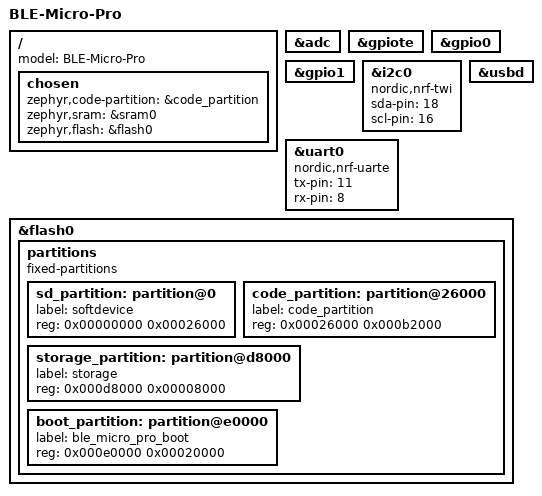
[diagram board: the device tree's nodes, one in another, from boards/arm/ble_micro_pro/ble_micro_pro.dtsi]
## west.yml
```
manifest:
  remotes:
    - name: zephyrproject-rtos
      url-base: https://github.com/zephyrproject-rtos
    - name: zmkfirmware
      url-base: https://github.com/zmkfirmware
  projects:
    - name: zephyr
      url: https://github.com/sekigon-gonnoc/zephyr
      revision: v4.1.0+nemu-link
      clone-depth: 1
      import:
        name-blocklist:
          - acpica
          - canopennode
          - cmsis-nn
          - cmsis_6
          - chre
          - ci-tools
          - edtt
          - fatfs
          - hal_adi
          - hal_altera
          - hal_ambiq
          - hal_atmel
          - hal_cypress
          - hal_espressif
          - hal_ethos_u
          - hal_gigadevice
          - hal_infineon
          - hal_intel
          - hal_microchip
          - hal_nuvoton
          - hal_nxp
          - hal_openisa
          - hal_quicklogic
          - hal_renesas
          - hal_rpi_pico
          - hal_silabs
          - hal_st
          - hal_stm32
          - hal_tdk
          - hal_telink
          - hal_ti
          - hal_wch
          - hal_wurthelektronik
          - hal_xtensa
          - hostap
          - liblc3
          - libmctp
          - libmetal
          - littlefs
          - loramac-node
          - lz4
          - mcuboot
          - mcumgr
          - mipi-sys-t
          - net-tools
          - nrf_hw_models
          - nrf_wifi
          - open-amp
          - openthread
          - percepio
          - psa-arch-tests
          - sof
          - tf-m-tests
          - tflite-micro
          - thrift
          - trusted-firmware-a
          - trusted-firmware-m
          - uoscore-uedhoc
          - zephyr-lang-rust
          - zscilib
    - name: lvgl
      revision: f1db87ee98f1810328a8419572fa42a3b5f352ae
      path: modules/lib/gui/lvgl
      remote: zmkfirmware
    - name: zmk-studio-messages
      url: https://github.com/sekigon-gonnoc/zmk-studio-messages
      revision: nemu-link
      path: modules/msgs/zmk-studio-messages
  group-filter: [+optional]
  self:
    west-commands: scripts/west-commands.yml
```

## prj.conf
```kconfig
CONFIG_APPLICATION_DEFINED_SYSCALL=y

# Use Zephyr's built-in Mbed TLS PSA backend for ZMK BLE crypto.
CONFIG_NRF_SECURITY=n
CONFIG_MBEDTLS_ENABLE_HEAP=y
CONFIG_MBEDTLS_HEAP_SIZE=4096
CONFIG_SETTINGS=y
CONFIG_ESB_MAX_PAYLOAD_LENGTH=64
CONFIG_SYSTEM_WORKQUEUE_STACK_SIZE=3072
CONFIG_ZMK_STUDIO_RPC_RX_BUF_SIZE=256
```

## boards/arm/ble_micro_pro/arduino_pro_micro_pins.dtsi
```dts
/*
 * Copyright (c) 2021 The ZMK Contributors
 *
 * SPDX-License-Identifier: MIT
 */

/ {
	pro_micro: connector {
		compatible = "arduino-pro-micro";
		#gpio-cells = <2>;
		gpio-map-mask = <0xffffffff 0xffffffc0>;
		gpio-map-pass-thru = <0 0x3f>;
		gpio-map
			= <0 0 &gpio0 8 0>		/* D0 */
			, <1 0 &gpio0 11 0>		/* D1 */
			, <2 0 &gpio0 18 0>		/* D2 */
			, <3 0 &gpio0 16 0>		/* D3 */
			, <4 0 &gpio0 19 0>		/* D4/A6 */
			, <5 0 &gpio0 20 0>		/* D5 */
			, <6 0 &gpio0 22 0>		/* D6/A7 */
			, <7 0 &gpio0 23 0>		/* D7 */
			, <8 0 &gpio1 0 0>		/* D8/A8 */
			, <9 0 &gpio1 3 0>		/* D9/A9 */
			, <10 0 &gpio0 9 0>		/* D10/A10 */
			, <16 0 &gpio0 10 0>	/* D16 */
			, <14 0 &gpio1 15 0>	/* D14 */
			, <15 0 &gpio1 14 0>	/* D15 */
			, <18 0 &gpio0 3 0>	/* D18/A0 */
			, <19 0 &gpio0 30 0>	/* D19/A1 */
			, <20 0 &gpio0 0 0>	/* D20/A2 */
			, <21 0 &gpio0 5 0>	/* D21/A3 */
			;
	};

	pro_micro_a: connector_a {
		compatible = "arduino-pro-micro";
		#gpio-cells = <2>;
		gpio-map-mask = <0xffffffff 0xffffffc0>;
		gpio-map-pass-thru = <0 0x3f>;
		gpio-map
			= <0 0 &gpio0 3 0>	/* D18/A0 */
			, <1 0 &gpio0 30 0>	/* D19/A1 */
			, <2 0 &gpio0 0 0>	/* D20/A2 */
			, <3 0 &gpio0 5 0>	/* D21/A3 */
			, <6 0 &gpio0 19 0>	/* D4/A6 */
			, <7 0 &gpio0 22 0>	/* D6/A7 */
			, <8 0 &gpio1 0 0>	/* D8/A8 */
			, <9 0 &gpio1 3 0>	/* D9/A9 */
			, <10 0 &gpio0 9 0>	/* D10/A10 */
			;
	};
};

pro_micro_d: &pro_micro {};
pro_micro_i2c: &i2c0 {};
pro_micro_spi: &spi0 {};
pro_micro_serial: &uart0 {};
```

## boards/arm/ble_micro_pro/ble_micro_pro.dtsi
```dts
/*
 * Copyright (c) 2021 The ZMK Contributors
 *
 * SPDX-License-Identifier: MIT
 */

#include <nordic/nrf52840_qiaa.dtsi>
#include "arduino_pro_micro_pins.dtsi"

/ {
	model = "BLE-Micro-Pro";

	chosen {
		zephyr,code-partition = &code_partition;
		zephyr,sram = &sram0;
		zephyr,flash = &flash0;
	};
};

&adc {
	status = "okay";
};

&gpiote {
	status = "okay";
};

&gpio0 {
	status = "okay";
};

&gpio1 {
	status = "okay";
};

&i2c0 {
	compatible = "nordic,nrf-twi";
	sda-pin = <18>;
	scl-pin = <16>;
};

&uart0 {
	compatible = "nordic,nrf-uarte";
	tx-pin = <11>;
	rx-pin = <8>;
};

&usbd {
	status = "okay";
};


&flash0 {
	/*
	 * For more information, see:
	 * http://docs.zephyrproject.org/latest/devices/dts/flash_partitions.html
	 */
	partitions {
		compatible = "fixed-partitions";
		#address-cells = <1>;
		#size-cells = <1>;

		sd_partition: partition@0 {
			label = "softdevice";
			reg = <0x00000000 0x00026000>;
		};
		code_partition: partition@26000 {
			label = "code_partition";
			reg = <0x00026000 0x000b2000>;
		};

		/*
		 * The flash starting at 0x000ec000 and ending at
		 * 0x000f3fff is reserved for use by the application.
		 */

		/*
		 * Storage partition will be used by FCB/LittleFS/NVS
		 * if enabled.
		 */
		storage_partition: partition@d8000 {
			label = "storage";
			reg = <0x000d8000 0x00008000>;
		};

		boot_partition: partition@e0000 {
			label = "ble_micro_pro_boot";
			reg = <0x000e0000 0x00020000>;
		};
	};
};
```

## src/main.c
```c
/*
 * Copyright (c) 2020 The ZMK Contributors
 *
 * SPDX-License-Identifier: MIT
 */

#include <zephyr/kernel.h>
#include <zephyr/device.h>
#include <zephyr/devicetree.h>
#include <zephyr/settings/settings.h>

#include <zephyr/logging/log.h>
LOG_MODULE_REGISTER(zmk, CONFIG_ZMK_LOG_LEVEL);

#if IS_ENABLED(CONFIG_ZMK_DISPLAY)

#include <zmk/display.h>
#include <lvgl.h>

#endif

int main(void) {
    LOG_INF("Welcome to ZMK!\n");

#if IS_ENABLED(CONFIG_SETTINGS)
    settings_subsys_init();
#if IS_ENABLED(CONFIG_ZMK_BEHAVIOR_LOCAL_ID_TYPE_SETTINGS_TABLE)
    settings_load_subtree("behavior");
#endif
    settings_load();
#endif

#ifdef CONFIG_ZMK_DISPLAY
    zmk_display_init();

#if IS_ENABLED(CONFIG_ARCH_POSIX)
    // Workaround for an SDL display issue:
    // https://github.com/zephyrproject-rtos/zephyr/issues/71410
    while (1) {
        lv_task_handler();
        k_sleep(K_MSEC(10));
    }
#endif

#endif /* CONFIG_ZMK_DISPLAY */

    return 0;
}
```

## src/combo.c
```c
/*
 * Copyright (c) 2020 The ZMK Contributors
 *
 * SPDX-License-Identifier: MIT
 */

#define DT_DRV_COMPAT zmk_combos

#include <zephyr/device.h>
#include <zephyr/logging/log.h>
#include <zephyr/sys/dlist.h>
#include <zephyr/sys/util.h>
#include <zephyr/kernel.h>

#include <drivers/behavior.h>

#include <zmk/behavior.h>
#include <zmk/event_manager.h>
#include <zmk/events/position_state_changed.h>
#include <zmk/events/keycode_state_changed.h>
#include <zmk/hid.h>
#include <zmk/matrix.h>
#include <zmk/keymap.h>
#include <zmk/virtual_key_position.h>

#if IS_ENABLED(CONFIG_ZMK_ESBR_RUNTIME_COMBO)
#include <zmk/esbr_runtime_combo/combo.h>
#endif
#if IS_ENABLED(CONFIG_ZMK_ESBR_RUNTIME_TAP_DANCE)
#include <zmk/esbr_runtime_tap_dance/tap_dance.h>
#endif

LOG_MODULE_DECLARE(zmk, CONFIG_ZMK_LOG_LEVEL);

#if DT_HAS_COMPAT_STATUS_OKAY(DT_DRV_COMPAT) || IS_ENABLED(CONFIG_ZMK_ESBR_RUNTIME_COMBO)

#if CONFIG_ZMK_COMBO_MAX_KEYS_PER_COMBO > 0

#warning                                                                                           \
    "CONFIG_ZMK_COMBO_MAX_KEYS_PER_COMBO is deprecated, and is auto-calculated from the devicetree now."

#endif

#if CONFIG_ZMK_COMBO_MAX_COMBOS_PER_KEY > 0

#warning "CONFIG_ZMK_COMBO_MAX_COMBOS_PER_KEY is deprecated, and is auto-calculated."

#endif

#if IS_ENABLED(CONFIG_ZMK_ESBR_RUNTIME_COMBO)
#define MAX_COMBO_KEYS ZMK_ESBR_RUNTIME_COMBO_MAX_POSITIONS
#define COMBO_COUNT ZMK_ESBR_RUNTIME_COMBO_MAX_SLOTS
#define BYTES_FOR_COMBOS_MASK 1
#else
#define COMBOS_KEYS_BYTE_ARRAY(node_id)                                                            \
    uint8_t _CONCAT(combo_prop_, node_id)[DT_PROP_LEN(node_id, key_positions)];

#define MAX_COMBO_KEYS sizeof(union {DT_INST_FOREACH_CHILD(0, COMBOS_KEYS_BYTE_ARRAY)})
#endif

struct combo_cfg {
    int32_t key_positions[MAX_COMBO_KEYS];
    int16_t key_position_len;
    int16_t require_prior_idle_ms;
    int32_t timeout_ms;
    uint32_t layer_mask;
    struct zmk_behavior_binding behavior;
    // if slow release is set, the combo releases when the last key is released.
    // otherwise, the combo releases when the first key is released.
    bool slow_release;
};

struct active_combo {
    uint16_t combo_idx;
    // key_positions_pressed is filled with key_positions when the combo is pressed.
    // The keys are removed from this array when they are released.
    // Once this array is empty, the behavior is released.
    uint16_t key_positions_pressed_count;
    struct zmk_position_state_changed_event key_positions_pressed[MAX_COMBO_KEYS];
};

#define PROP_BIT_AT_IDX(n, prop, idx) BIT(DT_PROP_BY_IDX(n, prop, idx))

#define NODE_PROP_BITMASK(n, prop)                                                                 \
    COND_CODE_1(DT_NODE_HAS_PROP(n, prop),                                                         \
                (DT_FOREACH_PROP_ELEM_SEP(n, prop, PROP_BIT_AT_IDX, (|))), (0))

#define GET_KEY_POSITION_MASK_PORTION(idx, n) ((NODE_PROP_BITMASK(n, key_positions) >> idx) & 0xFF)

#define COMBO_INST(n, positions)                                                                   \
    COND_CODE_1(IS_EQ(DT_PROP_LEN(n, key_positions), positions),                                   \
                (                                                                                  \
                    {                                                                              \
                        .timeout_ms = DT_PROP(n, timeout_ms),                                      \
                        .require_prior_idle_ms = DT_PROP(n, require_prior_idle_ms),                \
                        .key_positions = DT_PROP(n, key_positions),                                \
                        .key_position_len = DT_PROP_LEN(n, key_positions),                         \
                        .behavior = ZMK_KEYMAP_EXTRACT_BINDING(0, n),                              \
                        .slow_release = DT_PROP(n, slow_release),                                  \
                        .layer_mask = NODE_PROP_BITMASK(n, layers),                                \
                    }, ),                                                                          \
                ())

#define COMBO_CONFIGS_WITH_MATCHING_POSITIONS_LEN(positions, _ignore)                              \
    DT_INST_FOREACH_CHILD_VARGS(0, COMBO_INST, positions)

// We do some magic here to generate the `combos` array by "key position length", looping
// by key position length and on each iteration, only include entries where the `key-positions`
// length matches.
// Doing so allows our bitmasks to be "shorted key positions list first" when searching for matches.
// `20` is chosen as a reasonable limit, since the theoretical maximum number of keys you might
// reasonably press simultaneously with 10 fingers is 20 keys, two keys per finger.
#define COMBO_ONE(n) +1

#if DT_HAS_COMPAT_STATUS_OKAY(DT_DRV_COMPAT)
#define COMBO_CHILDREN_COUNT (0 DT_INST_FOREACH_CHILD(0, COMBO_ONE))
#else
#define COMBO_CHILDREN_COUNT 0
#endif

#if IS_ENABLED(CONFIG_ZMK_ESBR_RUNTIME_COMBO)
BUILD_ASSERT(COMBO_CHILDREN_COUNT == 0, "Runtime Combo cannot be combined with static ZMK combos");
static struct combo_cfg combos[COMBO_COUNT];
#define COMBO_TOTAL_COUNT COMBO_COUNT
#else
static const struct combo_cfg combos[] = {
    LISTIFY(20, COMBO_CONFIGS_WITH_MATCHING_POSITIONS_LEN, (), 0)};
#define COMBO_TOTAL_COUNT ARRAY_SIZE(combos)
#endif

// We need at least 4 bytes to avoid alignment issues
#if !IS_ENABLED(CONFIG_ZMK_ESBR_RUNTIME_COMBO)
#define BYTES_FOR_COMBOS_MASK MAX(1, DIV_ROUND_UP(COMBO_CHILDREN_COUNT, 32))
#endif

uint8_t pressed_keys_count = 0;
// set of keys pressed
struct zmk_position_state_changed_event pressed_keys[MAX_COMBO_KEYS] = {};
// the set of candidate combos based on the currently pressed_keys
uint32_t candidates[BYTES_FOR_COMBOS_MASK];
// the last candidate that was completely pressed
int16_t fully_pressed_combo = INT16_MAX;
// a lookup dict that maps a key position to all combos on that position
uint32_t combo_lookup[ZMK_KEYMAP_LEN][BYTES_FOR_COMBOS_MASK] = {};
// combos that have been activated and still have (some) keys pressed
// this array is always contiguous from 0.
struct active_combo active_combos[CONFIG_ZMK_COMBO_MAX_PRESSED_COMBOS] = {};
uint8_t active_combo_count = 0;

struct k_work_delayable timeout_task;
int64_t timeout_task_timeout_at;

// this keeps track of the last non-combo, non-mod key tap
int64_t last_tapped_timestamp = INT32_MIN;
// this keeps track of the last time a combo was pressed
int64_t last_combo_timestamp = INT32_MIN;

static void store_last_tapped(int64_t timestamp) {
    if (timestamp > last_combo_timestamp) {
        last_tapped_timestamp = timestamp;
    }
}

#if IS_ENABLED(CONFIG_ZMK_ESBR_RUNTIME_COMBO)
static void refresh_runtime_combos(void) {
    for (uint8_t i = 0; i < COMBO_COUNT; i++) {
        struct esbr_runtime_combo_config config;
        if (esbr_combo_slot_get(i, &config) != 0 || !config.enabled) {
            combos[i] = (struct combo_cfg){0};
            continue;
        }
        combos[i] = (struct combo_cfg){
            .key_position_len = config.count,
            .require_prior_idle_ms = 0,
            .timeout_ms = config.timeout_ms,
            .layer_mask = config.layer_mask,
            .behavior = config.binding,
            .slow_release = config.release_mode == 1,
        };
        for (uint8_t position = 0; position < config.count; position++) {
            combos[i].key_positions[position] = config.positions[position];
        }
    }
}

static bool runtime_combo_contains(const struct combo_cfg *combo, int32_t position) {
    for (int i = 0; i < combo->key_position_len; i++) {
        if (combo->key_positions[i] == position) {
            return true;
        }
    }
    return false;
}

static void runtime_combo_sync_busy(void) {
    bool busy[COMBO_COUNT] = {0};
    for (uint8_t i = 0; i < COMBO_COUNT; i++) {
        busy[i] = sys_bitfield_test_bit((mem_addr_t)&candidates, i);
    }
    for (uint8_t i = 0; i < active_combo_count; i++) {
        const uint16_t combo_idx = active_combos[i].combo_idx;
        if (combo_idx < COMBO_COUNT) {
            busy[combo_idx] = true;
        }
    }
    for (uint8_t i = 0; i < COMBO_COUNT; i++) {
        esbr_combo_slot_set_busy(i, busy[i]);
    }
}
#endif

// Store the combo key pointer in the combos array, one pointer for each key position
// The combos are sorted shortest-first, then by virtual-key-position.
static int initialize_combo(size_t index) {
    const struct combo_cfg *new_combo = &combos[index];

    for (size_t kp = 0; kp < new_combo->key_position_len; kp++) {
        sys_bitfield_set_bit((mem_addr_t)&combo_lookup[new_combo->key_positions[kp]], index);
    }

    return 0;
}

static bool combo_active_on_layer(const struct combo_cfg *combo, uint8_t layer) {
    if (!combo->layer_mask) {
        return true;
    }

    return combo->layer_mask & BIT(layer);
}

static bool is_quick_tap(const struct combo_cfg *combo, int64_t timestamp) {
    return (last_tapped_timestamp + combo->require_prior_idle_ms) > timestamp;
}

static int setup_candidates_for_first_keypress(int32_t position, int64_t timestamp) {
    int number_of_combo_candidates = 0;
    uint8_t highest_active_layer = zmk_keymap_highest_layer_active();

#if IS_ENABLED(CONFIG_ZMK_ESBR_RUNTIME_COMBO)
    for (size_t i = 0; i < COMBO_TOTAL_COUNT; i++) {
        const struct combo_cfg *combo = &combos[i];
        if (runtime_combo_contains(combo, position) &&
            combo_active_on_layer(combo, highest_active_layer) && !is_quick_tap(combo, timestamp)) {
            sys_bitfield_set_bit((mem_addr_t)&candidates, i);
            number_of_combo_candidates++;
        }
    }
#else
    for (size_t i = 0; i < COMBO_TOTAL_COUNT; i++) {
        if (sys_bitfield_test_bit((mem_addr_t)&combo_lookup[position], i)) {
            const struct combo_cfg *combo = &combos[i];
            if (combo_active_on_layer(combo, highest_active_layer) &&
                !is_quick_tap(combo, timestamp)) {
                sys_bitfield_set_bit((mem_addr_t)&candidates, i);
                number_of_combo_candidates++;
            }
            // LOG_DBG("combo timeout %d %d %d", position, i, candidates[i].timeout_at);
        }
    }
#endif

    return number_of_combo_candidates;
}

static inline uint8_t zero_one_or_more_bits(uint32_t field) {
    if (field == 0) {
        return 0;
    }
    if ((field & (field - 1)) == 0) {
        return 1;
    }
    return 2;
}

static int filter_candidates(int32_t position) {
    int matches = 0;
#if IS_ENABLED(CONFIG_ZMK_ESBR_RUNTIME_COMBO)
    for (size_t i = 0; i < COMBO_TOTAL_COUNT; i++) {
        if (!sys_bitfield_test_bit((mem_addr_t)&candidates, i)) {
            continue;
        }
        if (!runtime_combo_contains(&combos[i], position)) {
            sys_bitfield_clear_bit((mem_addr_t)&candidates, i);
        } else if (matches < 2) {
            matches++;
        }
    }
#else
    for (int i = 0; i < BYTES_FOR_COMBOS_MASK; i++) {
        candidates[i] &= combo_lookup[position][i];
        if (matches < 2) {
            matches += zero_one_or_more_bits(candidates[i]);
        }
    }
#endif

    LOG_DBG("combo matches after filter %d", matches);
    return matches;
}

static int64_t first_candidate_timeout() {
    if (pressed_keys_count == 0) {
        return LONG_MAX;
    }

    int64_t first_timeout = LONG_MAX;
    for (int i = 0; i < COMBO_TOTAL_COUNT; i++) {
        if (sys_bitfield_test_bit((mem_addr_t)&candidates, i)) {
            first_timeout = MIN(first_timeout, combos[i].timeout_ms);
        }
    }

    return pressed_keys[0].data.timestamp + first_timeout;
}

static inline bool candidate_is_completely_pressed(const struct combo_cfg *candidate) {
    // this code assumes set(pressed_keys) <= set(candidate->key_positions)
    // this invariant is enforced by filter_candidates
    // since events may have been reraised after clearing one or more slots at
    // the start of pressed_keys (see: release_pressed_keys), we have to check
    // that each key needed to trigger the combo was pressed, not just the last.
    return candidate->key_position_len == pressed_keys_count;
}

static int cleanup();

static int filter_timed_out_candidates(int64_t timestamp) {
    __ASSERT(pressed_keys_count > 0, "Searching for a candidate timeout with no keys pressed");

    int remaining_candidates = 0;
    for (int i = 0; i < COMBO_TOTAL_COUNT; i++) {
        if (sys_bitfield_test_bit((mem_addr_t)&candidates, i)) {

            if (pressed_keys[0].data.timestamp + combos[i].timeout_ms > timestamp) {
                remaining_candidates++;
            } else {
                sys_bitfield_clear_bit((mem_addr_t)&candidates, i);
            }
        }
    }

    LOG_DBG(
        "after filtering out timed out combo candidates: remaining_candidates=%d timestamp=%lld",
        remaining_candidates, timestamp);

    return remaining_candidates;
}

static int capture_pressed_key(const struct zmk_position_state_changed *ev) {
    if (pressed_keys_count == MAX_COMBO_KEYS) {
        return ZMK_EV_EVENT_BUBBLE;
    }

    pressed_keys[pressed_keys_count++] = copy_raised_zmk_position_state_changed(ev);
    return ZMK_EV_EVENT_CAPTURED;
}

const struct zmk_listener zmk_listener_combo;

static int release_pressed_keys() {
    uint8_t count = pressed_keys_count;
    pressed_keys_count = 0;
    for (int i = 0; i < count; i++) {
        struct zmk_position_state_changed_event *ev = &pressed_keys[i];
        if (i == 0) {
            LOG_DBG("combo: releasing position event %d", ev->data.position);
            ZMK_EVENT_RELEASE(*ev);
        } else {
            // reprocess events (see tests/combo/fully-overlapping-combos-3 for why this is needed)
            LOG_DBG("combo: reraising position event %d", ev->data.position);
            ZMK_EVENT_RAISE(*ev);
        }
    }

    return count;
}

static inline int press_combo_behavior(int combo_idx, const struct combo_cfg *combo,
                                       int32_t timestamp) {
    struct zmk_behavior_binding_event event = {
        .position = ZMK_VIRTUAL_KEY_POSITION_COMBO(combo_idx),
        .timestamp = timestamp,
#if IS_ENABLED(CONFIG_ZMK_SPLIT)
        .source = ZMK_POSITION_STATE_CHANGE_SOURCE_LOCAL,
#endif
    };

    last_combo_timestamp = timestamp;

    return zmk_behavior_invoke_binding(&combo->behavior, event, true);
}

static inline int release_combo_behavior(int combo_idx, const struct combo_cfg *combo,
                                         int32_t timestamp) {
    struct zmk_behavior_binding_event event = {
        .position = ZMK_VIRTUAL_KEY_POSITION_COMBO(combo_idx),
        .timestamp = timestamp,
#if IS_ENABLED(CONFIG_ZMK_SPLIT)
        .source = ZMK_POSITION_STATE_CHANGE_SOURCE_LOCAL,
#endif
    };

    return zmk_behavior_invoke_binding(&combo->behavior, event, false);
}

static void move_pressed_keys_to_active_combo(struct active_combo *active_combo) {

    int combo_length = MIN(pressed_keys_count, combos[active_combo->combo_idx].key_position_len);
    for (int i = 0; i < combo_length; i++) {
        active_combo->key_positions_pressed[i] = pressed_keys[i];
    }
    active_combo->key_positions_pressed_count = combo_length;

    // move any other pressed keys up
    for (int i = 0; i + combo_length < pressed_keys_count; i++) {
        pressed_keys[i] = pressed_keys[i + combo_length];
    }

    pressed_keys_count -= combo_length;
}

static struct active_combo *store_active_combo(int32_t combo_idx) {
    for (int i = 0; i < CONFIG_ZMK_COMBO_MAX_PRESSED_COMBOS; i++) {
        if (active_combos[i].combo_idx == UINT16_MAX) {
            active_combos[i].combo_idx = combo_idx;
            active_combo_count++;
            return &active_combos[i];
        }
    }
    LOG_ERR("Unable to store combo; already %d active. Increase "
            "CONFIG_ZMK_COMBO_MAX_PRESSED_COMBOS",
            CONFIG_ZMK_COMBO_MAX_PRESSED_COMBOS);
    return NULL;
}

static void activate_combo(int combo_idx) {
    struct active_combo *active_combo = store_active_combo(combo_idx);
    if (active_combo == NULL) {
        // unable to store combo
        release_pressed_keys();
        return;
    }
    move_pressed_keys_to_active_combo(active_combo);
    press_combo_behavior(combo_idx, &combos[combo_idx],
                         active_combo->key_positions_pressed[0].data.timestamp);
}

static void deactivate_combo(int active_combo_index) {
    active_combo_count--;
    if (active_combo_index != active_combo_count) {
        memcpy(&active_combos[active_combo_index], &active_combos[active_combo_count],
               sizeof(struct active_combo));
    }
    active_combos[active_combo_count] = (struct active_combo){0};
    active_combos[active_combo_count].combo_idx = UINT16_MAX;
}

/* returns true if a key was released. */
static bool release_combo_key(int32_t position, int64_t timestamp) {
    for (int combo_idx = 0; combo_idx < active_combo_count; combo_idx++) {
        struct active_combo *active_combo = &active_combos[combo_idx];

        bool key_released = false;
        bool all_keys_pressed = active_combo->key_positions_pressed_count ==
                                combos[active_combo->combo_idx].key_position_len;
        bool all_keys_released = true;
        for (int i = 0; i < active_combo->key_positions_pressed_count; i++) {
            if (key_released) {
                active_combo->key_positions_pressed[i - 1] = active_combo->key_positions_pressed[i];
                all_keys_released = false;
            } else if (active_combo->key_positions_pressed[i].data.position != position) {
                all_keys_released = false;
            } else { // position matches
                key_released = true;
            }
        }

        if (key_released) {
            active_combo->key_positions_pressed_count--;
            const struct combo_cfg *c = &combos[active_combo->combo_idx];
            if ((c->slow_release && all_keys_released) || (!c->slow_release && all_keys_pressed)) {
                release_combo_behavior(active_combo->combo_idx, c, timestamp);
            }
            if (all_keys_released) {
                deactivate_combo(combo_idx);
            }
            return true;
        }
    }
    return false;
}

static int cleanup() {
    k_work_cancel_delayable(&timeout_task);
    memset(candidates, 0, BYTES_FOR_COMBOS_MASK * sizeof(uint32_t));
    if (fully_pressed_combo != INT16_MAX) {
        activate_combo(fully_pressed_combo);
        fully_pressed_combo = INT16_MAX;
    }
    int released = release_pressed_keys();
#if IS_ENABLED(CONFIG_ZMK_ESBR_RUNTIME_COMBO)
    runtime_combo_sync_busy();
#endif
    return released;
}

static void update_timeout_task() {
    int64_t first_timeout = first_candidate_timeout();
    if (timeout_task_timeout_at == first_timeout) {
        return;
    }
    if (first_timeout == LLONG_MAX) {
        timeout_task_timeout_at = 0;
        k_work_cancel_delayable(&timeout_task);
        return;
    }
    if (k_work_schedule(&timeout_task, K_MSEC(first_timeout - k_uptime_get())) >= 0) {
        timeout_task_timeout_at = first_timeout;
    }
}

static int position_state_down(const zmk_event_t *ev, struct zmk_position_state_changed *data) {
    int num_candidates;
#if IS_ENABLED(CONFIG_ZMK_ESBR_RUNTIME_COMBO)
    refresh_runtime_combos();
#endif
    if (!pressed_keys_count) {
        num_candidates = setup_candidates_for_first_keypress(data->position, data->timestamp);
        if (num_candidates == 0) {
            return ZMK_EV_EVENT_BUBBLE;
        }
    } else {
        filter_timed_out_candidates(data->timestamp);
        num_candidates = filter_candidates(data->position);
    }

    LOG_DBG("combo: capturing position event %d", data->position);
    int ret = capture_pressed_key(data);
    update_timeout_task();
#if IS_ENABLED(CONFIG_ZMK_ESBR_RUNTIME_COMBO)
    runtime_combo_sync_busy();
#endif

    if (num_candidates) {
        for (int i = 0; i < COMBO_TOTAL_COUNT; i++) {
            if (sys_bitfield_test_bit((mem_addr_t)&candidates, i)) {
                const struct combo_cfg *candidate_combo = &combos[i];
                if (candidate_is_completely_pressed(candidate_combo)) {
                    fully_pressed_combo = i;
                    if (num_candidates == 1) {
                        cleanup();
                    }
                }

                return ret;
            }
        }
    } else {
        cleanup();
        return ret;
    }

    return -EINVAL;
}

static int position_state_up(const zmk_event_t *ev, struct zmk_position_state_changed *data) {
    int released_keys = cleanup();
    if (release_combo_key(data->position, data->timestamp)) {
#if IS_ENABLED(CONFIG_ZMK_ESBR_RUNTIME_COMBO)
        runtime_combo_sync_busy();
#endif
        return ZMK_EV_EVENT_HANDLED;
    }
    if (released_keys > 1) {
        // The second and further key down events are re-raised. To preserve
        // correct order for e.g. hold-taps, reraise the key up event too.
        struct zmk_position_state_changed_event dupe_ev =
            copy_raised_zmk_position_state_changed(data);
        ZMK_EVENT_RAISE(dupe_ev);
        return ZMK_EV_EVENT_CAPTURED;
    }
    return ZMK_EV_EVENT_BUBBLE;
}

static void combo_timeout_handler(struct k_work *item) {
    if (timeout_task_timeout_at == 0 || k_uptime_get() < timeout_task_timeout_at) {
        // timer was cancelled or rescheduled.
        return;
    }
    if (filter_timed_out_candidates(timeout_task_timeout_at) == 0) {
        LOG_DBG("CLEANUP!");
        cleanup();
    }
#if IS_ENABLED(CONFIG_ZMK_ESBR_RUNTIME_COMBO)
    runtime_combo_sync_busy();
#endif

    LOG_DBG("ABOUT TO UPDATE IN TIMEOUT");
    update_timeout_task();
}

static int position_state_changed_listener(const zmk_event_t *ev) {
    struct zmk_position_state_changed *data = as_zmk_position_state_changed(ev);
    if (data == NULL) {
        return ZMK_EV_EVENT_BUBBLE;
    }

#if IS_ENABLED(CONFIG_ZMK_ESBR_RUNTIME_TAP_DANCE)
    if (data->state) {
        esbr_tap_dance_position_interrupt(data->source, data->position, data->timestamp);
    }
#endif

    if (data->state) { // keydown
        return position_state_down(ev, data);
    } else { // keyup
        return position_state_up(ev, data);
    }
}

static int keycode_state_changed_listener(const zmk_event_t *eh) {
    struct zmk_keycode_state_changed *ev = as_zmk_keycode_state_changed(eh);
    if (ev->state && !is_mod(ev->usage_page, ev->keycode)) {
        store_last_tapped(ev->timestamp);
    }
    return ZMK_EV_EVENT_BUBBLE;
}

int behavior_combo_listener(const zmk_event_t *eh) {
    if (as_zmk_position_state_changed(eh) != NULL) {
        return position_state_changed_listener(eh);
    } else if (as_zmk_keycode_state_changed(eh) != NULL) {
        return keycode_state_changed_listener(eh);
    }
    return ZMK_EV_EVENT_BUBBLE;
}

ZMK_LISTENER(combo, behavior_combo_listener);
ZMK_SUBSCRIPTION(combo, zmk_position_state_changed);
ZMK_SUBSCRIPTION(combo, zmk_keycode_state_changed);

static int combo_init(void) {
    for (size_t i = 0; i < CONFIG_ZMK_COMBO_MAX_PRESSED_COMBOS; i++) {
        active_combos[i].combo_idx = UINT16_MAX;
    }

    k_work_init_delayable(&timeout_task, combo_timeout_handler);
    LOG_WRN("Have %d combos!", COMBO_TOTAL_COUNT);
#if IS_ENABLED(CONFIG_ZMK_ESBR_RUNTIME_COMBO)
    refresh_runtime_combos();
    runtime_combo_sync_busy();
#else
    for (int i = 0; i < COMBO_TOTAL_COUNT; i++) {
        initialize_combo(i);
    }
#endif
    return 0;
}

SYS_INIT(combo_init, APPLICATION, CONFIG_KERNEL_INIT_PRIORITY_DEFAULT);

#endif
```

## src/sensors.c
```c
/*
 * Copyright (c) 2020 The ZMK Contributors
 *
 * SPDX-License-Identifier: MIT
 */

#include <zephyr/drivers/sensor.h>
#include <zephyr/devicetree.h>
#include <zephyr/init.h>

#include <zephyr/logging/log.h>

LOG_MODULE_DECLARE(zmk, CONFIG_ZMK_LOG_LEVEL);

#include <zmk/sensors.h>
#include <zmk/event_manager.h>
#include <zmk/events/sensor_event.h>

#if ZMK_KEYMAP_HAS_SENSORS

struct sensors_item_cfg {
    const struct zmk_sensor_config *config;
    const struct device *dev;
    struct sensor_trigger trigger;
    uint8_t sensor_index;
};

#define _SENSOR_ITEM(idx, node)                                                                    \
    {                                                                                              \
        .dev = DEVICE_DT_GET_OR_NULL(node),                                                        \
        .trigger = {.type = SENSOR_TRIG_DATA_READY, .chan = SENSOR_CHAN_ROTATION},                 \
        .config = &configs[idx], .sensor_index = idx                                               \
    }
#define SENSOR_ITEM(idx, _i) _SENSOR_ITEM(idx, ZMK_KEYMAP_SENSORS_BY_IDX(idx))

#define PLUS_ONE(n) +1
#define ZMK_KEYMAP_SENSORS_CHILD_COUNT (0 DT_FOREACH_CHILD(ZMK_KEYMAP_SENSORS_NODE, PLUS_ONE))
#define SENSOR_CHILD_ITEM(node)                                                                    \
    {                                                                                              \
        .triggers_per_rotation =                                                                   \
            DT_PROP_OR(node, triggers_per_rotation,                                                \
                       DT_PROP_OR(ZMK_KEYMAP_SENSORS_NODE, triggers_per_rotation,                  \
                                  CONFIG_ZMK_KEYMAP_SENSORS_DEFAULT_TRIGGERS_PER_ROTATION))        \
    }
#define SENSOR_CHILD_DEFAULTS(idx, arg)                                                            \
    {                                                                                              \
        .triggers_per_rotation =                                                                   \
            DT_PROP_OR(ZMK_KEYMAP_SENSORS_NODE, triggers_per_rotation,                             \
                       CONFIG_ZMK_KEYMAP_SENSORS_DEFAULT_TRIGGERS_PER_ROTATION)                    \
    }

static struct zmk_sensor_config configs[] = {
#if ZMK_KEYMAP_SENSORS_CHILD_COUNT > 0
    DT_FOREACH_CHILD_SEP(ZMK_KEYMAP_SENSORS_NODE, SENSOR_CHILD_ITEM, (, ))
#else
    LISTIFY(ZMK_KEYMAP_SENSORS_LEN, SENSOR_CHILD_DEFAULTS, (, ), 0)
#endif
};

static struct sensors_item_cfg sensors[] = {LISTIFY(ZMK_KEYMAP_SENSORS_LEN, SENSOR_ITEM, (, ), 0)};

static ATOMIC_DEFINE(pending_sensors, ZMK_KEYMAP_SENSORS_LEN);

const struct zmk_sensor_config *zmk_sensors_get_config_at_index(uint8_t sensor_index) {
    if (sensor_index > ARRAY_SIZE(configs)) {
        return NULL;
    }

    return &configs[sensor_index];
}

static void trigger_sensor_data_for_position(uint32_t sensor_index) {
    int err;
    const struct sensors_item_cfg *item = &sensors[sensor_index];

    err = sensor_sample_fetch(item->dev);
    if (err) {
        LOG_WRN("Failed to fetch sample from device %d", err);
        return;
    }

    struct sensor_value value = {0};
    err = sensor_channel_get(item->dev, item->trigger.chan, &value);

    if (err) {
        LOG_WRN("Failed to get channel data from device %d", err);
        return;
    }

    raise_zmk_sensor_event(
        (struct zmk_sensor_event){.sensor_index = item->sensor_index,
                                  .channel_data_size = 1,
                                  .channel_data = {(struct zmk_sensor_channel_data){
                                      .value = value, .channel = item->trigger.chan}},
                                  .timestamp = k_uptime_get()});
}

static void run_sensors_data_trigger(struct k_work *work) {
    for (int i = 0; i < ARRAY_SIZE(sensors); i++) {
        if (atomic_test_and_clear_bit(pending_sensors, i)) {
            trigger_sensor_data_for_position(i);
        }
    }
}

K_WORK_DEFINE(sensor_data_work, run_sensors_data_trigger);

static void zmk_sensors_trigger_handler(const struct device *dev,
                                        const struct sensor_trigger *trigger) {
    const struct sensors_item_cfg *test_item =
        CONTAINER_OF(trigger, struct sensors_item_cfg, trigger);
    int sensor_index = test_item - sensors;

    if (sensor_index < 0 || sensor_index >= ARRAY_SIZE(sensors)) {
        LOG_ERR("Invalid sensor item triggered our callback (%d)", sensor_index);
        return;
    }

    if (k_is_in_isr()) {
        atomic_set_bit(pending_sensors, sensor_index);
        k_work_submit(&sensor_data_work);
    } else {
        trigger_sensor_data_for_position(sensor_index);
    }
}

static void zmk_sensors_init_item(uint8_t i) {
    LOG_DBG("Init sensor at index %d", i);

    if (!sensors[i].dev) {
        LOG_DBG("No local device for %d", i);
        return;
    }

    int err = sensor_trigger_set(sensors[i].dev, &sensors[i].trigger, zmk_sensors_trigger_handler);
    if (err) {
        LOG_WRN("Failed to set sensor trigger (%d)", err);
    }
}

#define SENSOR_INIT(idx, _t) zmk_sensors_init_item(idx);

static int zmk_sensors_init(void) {
    LISTIFY(ZMK_KEYMAP_SENSORS_LEN, SENSOR_INIT, (), 0)

    return 0;
}

SYS_INIT(zmk_sensors_init, APPLICATION, CONFIG_APPLICATION_INIT_PRIORITY);

#endif /* ZMK_KEYMAP_HAS_SENSORS */
```

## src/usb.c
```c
/*
 * Copyright (c) 2020 The ZMK Contributors
 *
 * SPDX-License-Identifier: MIT
 */

#include <zephyr/device.h>
#include <zephyr/init.h>

#include <zephyr/usb/usb_device.h>
#include <zephyr/usb/class/usb_hid.h>

#include <zmk/hid.h>
#include <zmk/keymap.h>
#include <zmk/event_manager.h>
#include <zmk/events/usb_conn_state_changed.h>

#include <zmk/usb_hid.h>

LOG_MODULE_DECLARE(zmk, CONFIG_ZMK_LOG_LEVEL);

static enum usb_dc_status_code usb_status = USB_DC_UNKNOWN;
static bool is_configured;

static void raise_usb_status_changed_event(struct k_work *_work) {
    raise_zmk_usb_conn_state_changed(
        (struct zmk_usb_conn_state_changed){.conn_state = zmk_usb_get_conn_state()});
}

K_WORK_DEFINE(usb_status_notifier_work, raise_usb_status_changed_event);

enum usb_dc_status_code zmk_usb_get_status(void) { return usb_status; }

enum zmk_usb_conn_state zmk_usb_get_conn_state(void) {
    // LOG_DBG("state: %d", usb_status);
    switch (usb_status) {
    case USB_DC_SUSPEND:
    case USB_DC_CONFIGURED:
    case USB_DC_RESUME:
    case USB_DC_CLEAR_HALT:
    case USB_DC_SOF:
        return ZMK_USB_CONN_HID;

    case USB_DC_DISCONNECTED:
    case USB_DC_UNKNOWN:
        return ZMK_USB_CONN_NONE;

    default:
        return ZMK_USB_CONN_POWERED;
    }
}

bool zmk_usb_is_hid_ready(void) {
    return zmk_usb_get_conn_state() == ZMK_USB_CONN_HID && is_configured;
}

void usb_status_cb(enum usb_dc_status_code status, const uint8_t *params) {
    // Start-of-frame and interface selection events do not change ZMK's USB
    // connection state. In particular, UAC alternate setting changes must not
    // make the configured HID/RPC endpoint appear disconnected.
    if (status == USB_DC_SOF || status == USB_DC_INTERFACE) {
        return;
    }

#if IS_ENABLED(CONFIG_ZMK_USB_BOOT)
    if (status == USB_DC_RESET) {
        zmk_usb_hid_set_protocol(HID_PROTOCOL_REPORT);
    }
#endif
    usb_status = status;
    if (zmk_usb_get_conn_state() == ZMK_USB_CONN_HID) {
        is_configured |= usb_status == USB_DC_CONFIGURED;
    } else {
        is_configured = false;
    }
    k_work_submit(&usb_status_notifier_work);
};

static int zmk_usb_init(void) {
    int usb_enable_ret;

    usb_enable_ret = usb_enable(usb_status_cb);

    if (usb_enable_ret != 0) {
        LOG_ERR("Unable to enable USB");
        return -EINVAL;
    }

    return 0;
}

SYS_INIT(zmk_usb_init, APPLICATION, CONFIG_ZMK_USB_INIT_PRIORITY);
```

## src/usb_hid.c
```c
/*
 * Copyright (c) 2020 The ZMK Contributors
 *
 * SPDX-License-Identifier: MIT
 */

#include <zephyr/device.h>
#include <zephyr/init.h>

#include <zephyr/usb/usb_device.h>
#include <zephyr/usb/class/usb_hid.h>

#ifdef CONFIG_ZMK_NEMU_LINK
#define NEMU_LINK_USB_FEATURE_REPORT
#endif
#include <zmk/usb.h>
#include <zmk/hid.h>
#if IS_ENABLED(CONFIG_ZMK_DEV_DEBUG_HID)
#include <zmk/dev_debug/hid.h>
#endif
#ifdef CONFIG_ZMK_NEMU_LINK
#include <zmk/nemu_link/hid_feature_report.h>
#endif
#include <zmk/keymap.h>

#if IS_ENABLED(CONFIG_ZMK_POINTING_SMOOTH_SCROLLING)
#include <zmk/pointing/resolution_multipliers.h>
#endif // IS_ENABLED(CONFIG_ZMK_POINTING_SMOOTH_SCROLLING)

#if IS_ENABLED(CONFIG_ZMK_HID_INDICATORS)
#include <zmk/hid_indicators.h>
#endif // IS_ENABLED(CONFIG_ZMK_HID_INDICATORS)

#include <zmk/event_manager.h>

LOG_MODULE_DECLARE(zmk, CONFIG_ZMK_LOG_LEVEL);

static const struct device *hid_dev;

static K_SEM_DEFINE(hid_sem, 1, 1);

static void in_ready_cb(const struct device *dev) { k_sem_give(&hid_sem); }

#define HID_GET_REPORT_TYPE_MASK 0xff00
#define HID_GET_REPORT_ID_MASK 0x00ff

#define HID_REPORT_TYPE_INPUT 0x100
#define HID_REPORT_TYPE_OUTPUT 0x200
#define HID_REPORT_TYPE_FEATURE 0x300

#if IS_ENABLED(CONFIG_ZMK_USB_BOOT)
static uint8_t hid_protocol = HID_PROTOCOL_REPORT;

static void set_proto_cb(const struct device *dev, uint8_t protocol) { hid_protocol = protocol; }

void zmk_usb_hid_set_protocol(uint8_t protocol) { hid_protocol = protocol; }
#endif /* IS_ENABLED(CONFIG_ZMK_USB_BOOT) */

static uint8_t *get_keyboard_report(size_t *len) {
#if IS_ENABLED(CONFIG_ZMK_USB_BOOT)
    if (hid_protocol != HID_PROTOCOL_REPORT) {
        zmk_hid_boot_report_t *boot_report = zmk_hid_get_boot_report();
        *len = sizeof(*boot_report);
        return (uint8_t *)boot_report;
    }
#endif
    struct zmk_hid_keyboard_report *report = zmk_hid_get_keyboard_report();
    *len = sizeof(*report);
    return (uint8_t *)report;
}

static int get_report_cb(const struct device *dev, struct usb_setup_packet *setup, int32_t *len,
                         uint8_t **data) {
    switch (setup->wValue & HID_GET_REPORT_TYPE_MASK) {
    case HID_REPORT_TYPE_FEATURE:
        switch (setup->wValue & HID_GET_REPORT_ID_MASK) {
#if IS_ENABLED(CONFIG_ZMK_DEV_DEBUG_HID)
        case ZMK_HID_REPORT_ID_DEV_DEBUG: {
            static uint8_t debug_report[ZMK_DEV_DEBUG_HID_REPORT_SIZE];
            int rc = zmk_dev_debug_hid_get_report(debug_report, sizeof(debug_report));
            if (rc) {
                return rc;
            }
            *len = sizeof(debug_report);
            *data = debug_report;
            break;
        }
#endif
#ifdef CONFIG_ZMK_NEMU_LINK
        case ZMK_HID_REPORT_ID_NEMU_LINK_FEATURE: {
            static uint8_t feature_report[NEMU_LINK_HID_FEATURE_REPORT_SIZE];
            int rc = nemu_link_hid_feature_report_get(feature_report);
            if (rc) {
                return rc;
            }
            *len = sizeof(feature_report);
            *data = feature_report;
            break;
        }
#endif
#if IS_ENABLED(CONFIG_ZMK_POINTING_SMOOTH_SCROLLING)
        case ZMK_HID_REPORT_ID_MOUSE:
            static struct zmk_hid_mouse_resolution_feature_report res_feature_report;

            struct zmk_endpoint_instance endpoint = {
                .transport = ZMK_TRANSPORT_USB,
            };

            *len = sizeof(struct zmk_hid_mouse_resolution_feature_report);
            struct zmk_pointing_resolution_multipliers mult =
                zmk_pointing_resolution_multipliers_get_profile(endpoint);

            res_feature_report.body.wheel_res = mult.wheel;
            res_feature_report.body.hwheel_res = mult.hor_wheel;
            *data = (uint8_t *)&res_feature_report;
            break;
#endif // IS_ENABLED(CONFIG_ZMK_POINTING_SMOOTH_SCROLLING)
        default:
            return -ENOTSUP;
        }
        break;
    case HID_REPORT_TYPE_INPUT:
        switch (setup->wValue & HID_GET_REPORT_ID_MASK) {
        case ZMK_HID_REPORT_ID_KEYBOARD: {
            size_t size;
            *data = get_keyboard_report(&size);
            *len = (int32_t)size;
            break;
        }
        case ZMK_HID_REPORT_ID_CONSUMER: {
            struct zmk_hid_consumer_report *report = zmk_hid_get_consumer_report();
            *data = (uint8_t *)report;
            *len = sizeof(*report);
            break;
        }
        default:
            LOG_ERR("Invalid report ID %d requested", setup->wValue & HID_GET_REPORT_ID_MASK);
            return -EINVAL;
        }
        break;
    default:
        /*
         * 7.2.1 of the HID v1.11 spec is unclear about handling requests for reports that do not
         * exist For requested reports that aren't input reports, return -ENOTSUP like the Zephyr
         * subsys does
         */
        LOG_ERR("Unsupported report type %d requested", (setup->wValue & HID_GET_REPORT_TYPE_MASK)
                                                            << 8);
        return -ENOTSUP;
    }

    return 0;
}

static int set_report_cb(const struct device *dev, struct usb_setup_packet *setup, int32_t *len,
                         uint8_t **data) {
    switch (setup->wValue & HID_GET_REPORT_TYPE_MASK) {
    case HID_REPORT_TYPE_FEATURE:
        switch (setup->wValue & HID_GET_REPORT_ID_MASK) {
#if IS_ENABLED(CONFIG_ZMK_DEV_DEBUG_HID)
        case ZMK_HID_REPORT_ID_DEV_DEBUG:
            return zmk_dev_debug_hid_set_report(*data, *len);
#endif
#ifdef CONFIG_ZMK_NEMU_LINK
        case ZMK_HID_REPORT_ID_NEMU_LINK_FEATURE:
            return nemu_link_hid_feature_report_set(*data, *len);
#endif
#if IS_ENABLED(CONFIG_ZMK_POINTING_SMOOTH_SCROLLING)
        case ZMK_HID_REPORT_ID_MOUSE:
            if (*len != sizeof(struct zmk_hid_mouse_resolution_feature_report)) {
                return -EINVAL;
            }

            struct zmk_hid_mouse_resolution_feature_report *report =
                (struct zmk_hid_mouse_resolution_feature_report *)*data;
            struct zmk_endpoint_instance endpoint = {
                .transport = ZMK_TRANSPORT_USB,
            };

            zmk_pointing_resolution_multipliers_process_report(&report->body, endpoint);

            break;
#endif // IS_ENABLED(CONFIG_ZMK_POINTING_SMOOTH_SCROLLING)
        default:
            return -ENOTSUP;
        }
        break;

    case HID_REPORT_TYPE_OUTPUT:
        switch (setup->wValue & HID_GET_REPORT_ID_MASK) {
#if IS_ENABLED(CONFIG_ZMK_HID_INDICATORS)
        case ZMK_HID_REPORT_ID_LEDS:
            if (*len != sizeof(struct zmk_hid_led_report)) {
                LOG_ERR("LED set report is malformed: length=%d", *len);
                return -EINVAL;
            } else {
                struct zmk_hid_led_report *report = (struct zmk_hid_led_report *)*data;
                struct zmk_endpoint_instance endpoint = {
                    .transport = ZMK_TRANSPORT_USB,
                };
                zmk_hid_indicators_process_report(&report->body, endpoint);
            }
            break;
#endif // IS_ENABLED(CONFIG_ZMK_HID_INDICATORS)
        default:
            LOG_ERR("Invalid report ID %d requested", setup->wValue & HID_GET_REPORT_ID_MASK);
            return -EINVAL;
        }
        break;
    default:
        LOG_ERR("Unsupported report type %d requested",
                (setup->wValue & HID_GET_REPORT_TYPE_MASK) >> 8);
        return -ENOTSUP;
    }

    return 0;
}

static const struct hid_ops ops = {
#if IS_ENABLED(CONFIG_ZMK_USB_BOOT)
    .protocol_change = set_proto_cb,
#endif
    .int_in_ready = in_ready_cb,
    .get_report = get_report_cb,
    .set_report = set_report_cb,
};

static int zmk_usb_hid_send_report(const uint8_t *report, size_t len) {
    switch (zmk_usb_get_status()) {
    case USB_DC_SUSPEND:
        return usb_wakeup_request();
    case USB_DC_ERROR:
    case USB_DC_RESET:
    case USB_DC_DISCONNECTED:
    case USB_DC_UNKNOWN:
        return -ENODEV;
    default:
        k_sem_take(&hid_sem, K_MSEC(30));
        int err = hid_int_ep_write(hid_dev, report, len, NULL);

        if (err) {
            k_sem_give(&hid_sem);
        }

        return err;
    }
}

int zmk_usb_hid_send_keyboard_report(void) {
    size_t len;
    uint8_t *report = get_keyboard_report(&len);
    return zmk_usb_hid_send_report(report, len);
}

int zmk_usb_hid_send_consumer_report(void) {
#if IS_ENABLED(CONFIG_ZMK_USB_BOOT)
    if (hid_protocol == HID_PROTOCOL_BOOT) {
        return -ENOTSUP;
    }
#endif /* IS_ENABLED(CONFIG_ZMK_USB_BOOT) */

    struct zmk_hid_consumer_report *report = zmk_hid_get_consumer_report();
    return zmk_usb_hid_send_report((uint8_t *)report, sizeof(*report));
}

#if IS_ENABLED(CONFIG_ZMK_POINTING)
int zmk_usb_hid_send_mouse_report() {
#if IS_ENABLED(CONFIG_ZMK_USB_BOOT)
    if (hid_protocol == HID_PROTOCOL_BOOT) {
        return -ENOTSUP;
    }
#endif /* IS_ENABLED(CONFIG_ZMK_USB_BOOT) */

    struct zmk_hid_mouse_report *report = zmk_hid_get_mouse_report();
    return zmk_usb_hid_send_report((uint8_t *)report, sizeof(*report));
}
#endif // IS_ENABLED(CONFIG_ZMK_POINTING)

static int zmk_usb_hid_init(void) {
    hid_dev = device_get_binding("HID_0");
    if (hid_dev == NULL) {
        LOG_ERR("Unable to locate HID device");
        return -EINVAL;
    }

    usb_hid_register_device(hid_dev, zmk_hid_report_desc, sizeof(zmk_hid_report_desc), &ops);

#if IS_ENABLED(CONFIG_ZMK_USB_BOOT)
    usb_hid_set_proto_code(hid_dev, HID_BOOT_IFACE_CODE_KEYBOARD);
#endif /* IS_ENABLED(CONFIG_ZMK_USB_BOOT) */

    usb_hid_init(hid_dev);

    return 0;
}

SYS_INIT(zmk_usb_hid_init, APPLICATION, CONFIG_ZMK_USB_HID_INIT_PRIORITY);
```
